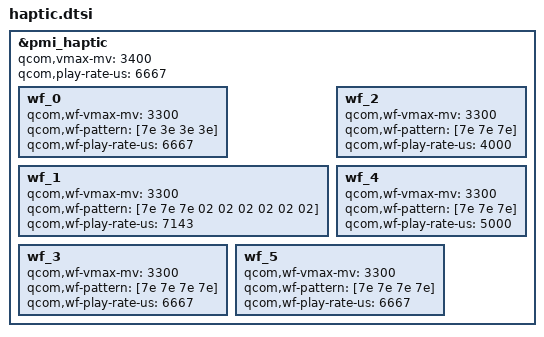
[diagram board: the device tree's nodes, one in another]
/* Haptics */
&pmi_haptic {
	status = "okay";
	qcom,vmax-mv = <3400>;
	qcom,play-rate-us = <6667>;
	wf_0 {
		qcom,wf-vmax-mv = <3300>;
		qcom,wf-pattern = [7e 3e 3e 3e];
		qcom,wf-play-rate-us = <6667>;
	};
	wf_1 {
		qcom,wf-vmax-mv = <3300>;
		qcom,wf-pattern = [7e 7e 7e 02 02 02 02 02 02];
		qcom,wf-play-rate-us = <7143>;
	};
	wf_2 {
		qcom,wf-vmax-mv = <3300>;
		qcom,wf-pattern = [7e 7e 7e];
		qcom,wf-play-rate-us = <4000>;
	};
	wf_3 {
		qcom,wf-vmax-mv = <3300>;
		qcom,wf-pattern = [7e 7e 7e 7e];
		qcom,wf-play-rate-us = <6667>;
	};
	wf_4 {
		qcom,wf-vmax-mv = <3300>;
		qcom,wf-pattern = [7e 7e 7e];
		qcom,wf-play-rate-us = <5000>;
	};
	wf_5 {
		qcom,wf-vmax-mv = <3300>;
		qcom,wf-pattern = [7e 7e 7e 7e];
		qcom,wf-play-rate-us = <6667>;
	};
};
